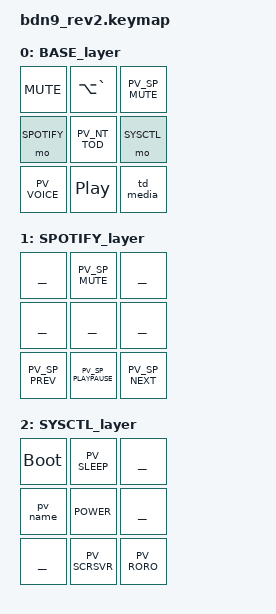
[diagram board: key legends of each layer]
#undef ZMK_BEHAVIORS_KEEP_ALL

#include <behaviors.dtsi>
#include <dt-bindings/zmk/keys.h>
#include <dt-bindings/zmk/rgb.h>

#include "pvinis_keys.dtsi"

&sensors {
	status = "okay";
	sensors = <&left_encoder &mid_encoder &right_encoder>;
};

&left_encoder { status = "okay"; };
// &mid_encoder { status = "okay"; };
&right_encoder { status = "okay"; };

#define BASE    0
#define SPOTIFY 1
#define SYSCTL  2


/ {
	macros {
		// TODO: at some point, make this into a macro with something like SEND_STRING from qmk. apparently this doesnt exist yet in zmk.
		ZMK_MACRO(
		pv_name,
		bindings = <&kp B &kp D &kp N &kp N9 &kp UNDERSCORE &kp R &kp E &kp V &kp N2>;
		wait-ms = <30>;
		tap-ms = <30>;
		)
	};

	behaviors {
		td_media: tap_dance_media {
			compatible = "zmk,behavior-tap-dance";
			#binding-cells = <0>;
			tapping-term-ms = <200>;
			bindings = <&kp C_PLAY_PAUSE>, <&kp C_NEXT>, <&kp C_PREV>;
		};
	};

	keymap {
		compatible = "zmk,keymap";

		BASE_layer {
			bindings = <
			&kp C_MUTE    &kp LA(GRAVE)     &kp PV_SP_MUTE
			&mo SPOTIFY   &kp PV_NT_TOD     &mo SYSCTL
			&kp PV_VOICE  &kp C_PLAY_PAUSE  &td_media
			>;
			sensor-bindings = <&inc_dec_kp C_VOL_UP C_VOL_DN &inc_dec_kp X X &inc_dec_kp PV_SP_VOLU PV_SP_VOLD>;
		};

		SPOTIFY_layer {
			bindings = <
			______          &kp PV_SP_MUTE       ______
			______          ______               ______
			&kp PV_SP_PREV  &kp PV_SP_PLAYPAUSE  &kp PV_SP_NEXT
			>;
			sensor-bindings = <&inc_dec_kp C_VOL_UP C_VOL_DN &inc_dec_kp X X &inc_dec_kp PV_SP_VOLU PV_SP_VOLD>;
		};

		SYSCTL_layer {
			bindings = <
			&bootloader  &kp PV_SLEEP   ______
			&pv_name     &kp C_POWER    ______
			______       &kp PV_SCRSVR  &kp PV_RORO
			>;
			sensor-bindings = <&inc_dec_kp C_VOL_UP C_VOL_DN &inc_dec_kp X X &inc_dec_kp PV_SP_VOLU PV_SP_VOLD>;
		};
	};
};
